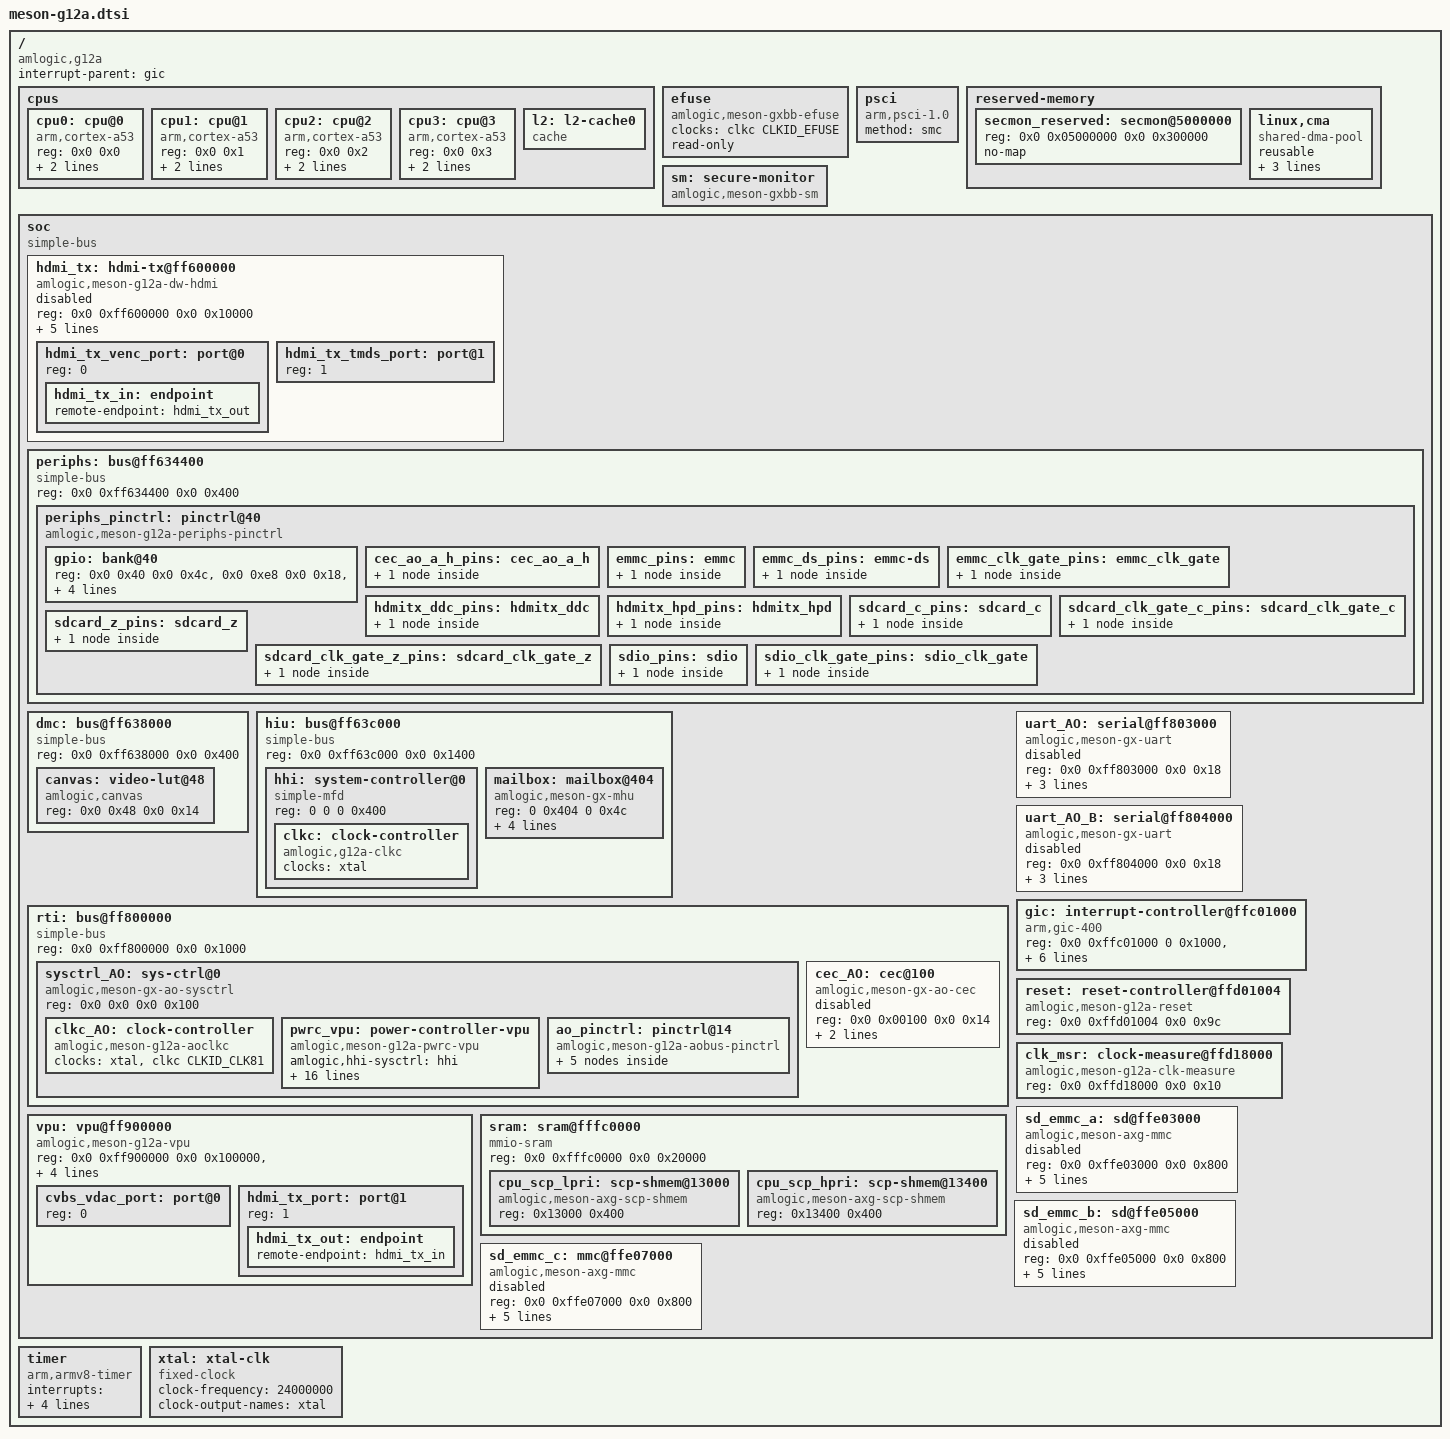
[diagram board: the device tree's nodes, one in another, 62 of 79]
// SPDX-License-Identifier: (GPL-2.0+ OR MIT)
/*
 * Copyright (c) 2018 Amlogic, Inc. All rights reserved.
 */

#include <dt-bindings/gpio/gpio.h>
#include <dt-bindings/clock/g12a-clkc.h>
#include <dt-bindings/gpio/gpio.h>
#include <dt-bindings/gpio/meson-g12a-gpio.h>
#include <dt-bindings/clock/g12a-aoclkc.h>
#include <dt-bindings/reset/g12a-aoclkc.h>
#include <dt-bindings/interrupt-controller/irq.h>
#include <dt-bindings/interrupt-controller/arm-gic.h>
#include <dt-bindings/reset/amlogic,meson-g12a-reset.h>

/ {
	compatible = "amlogic,g12a";

	interrupt-parent = <&gic>;
	#address-cells = <2>;
	#size-cells = <2>;

	cpus {
		#address-cells = <0x2>;
		#size-cells = <0x0>;

		cpu0: cpu@0 {
			device_type = "cpu";
			compatible = "arm,cortex-a53", "arm,armv8";
			reg = <0x0 0x0>;
			enable-method = "psci";
			next-level-cache = <&l2>;
		};

		cpu1: cpu@1 {
			device_type = "cpu";
			compatible = "arm,cortex-a53", "arm,armv8";
			reg = <0x0 0x1>;
			enable-method = "psci";
			next-level-cache = <&l2>;
		};

		cpu2: cpu@2 {
			device_type = "cpu";
			compatible = "arm,cortex-a53", "arm,armv8";
			reg = <0x0 0x2>;
			enable-method = "psci";
			next-level-cache = <&l2>;
		};

		cpu3: cpu@3 {
			device_type = "cpu";
			compatible = "arm,cortex-a53", "arm,armv8";
			reg = <0x0 0x3>;
			enable-method = "psci";
			next-level-cache = <&l2>;
		};

		l2: l2-cache0 {
			compatible = "cache";
		};
	};

	efuse: efuse {
		compatible = "amlogic,meson-gxbb-efuse";
		clocks = <&clkc CLKID_EFUSE>;
		#address-cells = <1>;
		#size-cells = <1>;
		read-only;
	};

	psci {
		compatible = "arm,psci-1.0";
		method = "smc";
	};

	reserved-memory {
		#address-cells = <2>;
		#size-cells = <2>;
		ranges;

		/* 3 MiB reserved for ARM Trusted Firmware (BL31) */
		secmon_reserved: secmon@5000000 {
			reg = <0x0 0x05000000 0x0 0x300000>;
			no-map;
		};

		linux,cma {
			compatible = "shared-dma-pool";
			reusable;
			size = <0x0 0x10000000>;
			alignment = <0x0 0x400000>;
			linux,cma-default;
		};
	};

	sm: secure-monitor {
		compatible = "amlogic,meson-gxbb-sm";
	};

	soc {
		compatible = "simple-bus";
		#address-cells = <2>;
		#size-cells = <2>;
		ranges;

		hdmi_tx: hdmi-tx@ff600000 {
			compatible = "amlogic,meson-g12a-dw-hdmi";
			reg = <0x0 0xff600000 0x0 0x10000>;
			interrupts = <GIC_SPI 57 IRQ_TYPE_EDGE_RISING>;
			resets = <&reset RESET_HDMITX_CAPB3>,
				 <&reset RESET_HDMITX_PHY>,
				 <&reset RESET_HDMITX>;
			reset-names = "hdmitx_apb", "hdmitx", "hdmitx_phy";
			clocks = <&clkc CLKID_HTX_PCLK>,
				 <&clkc CLKID_CLK81>,
				 <&clkc CLKID_VPU_INTR>;
			clock-names = "isfr", "iahb", "venci";
			#address-cells = <1>;
			#size-cells = <0>;
			status = "disabled";

			/* VPU VENC Input */
			hdmi_tx_venc_port: port@0 {
				reg = <0>;

				hdmi_tx_in: endpoint {
					remote-endpoint = <&hdmi_tx_out>;
				};
			};

			/* TMDS Output */
			hdmi_tx_tmds_port: port@1 {
				reg = <1>;
			};
		};

		periphs: bus@ff634400 {
			compatible = "simple-bus";
			reg = <0x0 0xff634400 0x0 0x400>;
			#address-cells = <2>;
			#size-cells = <2>;
			ranges = <0x0 0x0 0x0 0xff634400 0x0 0x400>;

			periphs_pinctrl: pinctrl@40 {
				compatible = "amlogic,meson-g12a-periphs-pinctrl";
				#address-cells = <2>;
				#size-cells = <2>;
				ranges;

				gpio: bank@40 {
					reg = <0x0 0x40  0x0 0x4c>,
					      <0x0 0xe8  0x0 0x18>,
					      <0x0 0x120 0x0 0x18>,
					      <0x0 0x2c0 0x0 0x40>,
					      <0x0 0x340 0x0 0x1c>;
					reg-names = "gpio",
						    "pull",
						    "pull-enable",
						    "mux",
						    "ds";
					gpio-controller;
					#gpio-cells = <2>;
					gpio-ranges = <&periphs_pinctrl 0 0 86>;
				};

				cec_ao_a_h_pins: cec_ao_a_h {
					mux {
						groups = "cec_ao_a_h";
						funcion = "cec_ao_a_h";
						bias-disable;
					};
				};

				emmc_pins: emmc {
					mux {
						groups = "emmc_nand_d0",
							 "emmc_nand_d1",
							 "emmc_nand_d2",
							 "emmc_nand_d3",
							 "emmc_nand_d4",
							 "emmc_nand_d5",
							 "emmc_nand_d6",
							 "emmc_nand_d7",
							 "emmc_clk",
							 "emmc_cmd";
						function = "emmc";
						bias-disable;
					};
				};

				emmc_ds_pins: emmc-ds {
					mux {
						groups = "emmc_nand_ds";
						function = "emmc";
						bias-disable;
					};
				};

				emmc_clk_gate_pins: emmc_clk_gate {
					mux {
						groups = "BOOT_8";
						function = "gpio_periphs";
						bias-pull-down;
					};
				};

				hdmitx_ddc_pins: hdmitx_ddc {
					mux {
						groups = "hdmitx_sda",
							 "hdmitx_sck";
						function = "hdmitx";
						bias-disable;
					};
				};

				hdmitx_hpd_pins: hdmitx_hpd {
					mux {
						groups = "hdmitx_hpd_in";
						function = "hdmitx";
						bias-disable;
					};
				};

				sdcard_c_pins: sdcard_c {
					mux {
						groups = "sdcard_d0_c",
							 "sdcard_d1_c",
							 "sdcard_d2_c",
							 "sdcard_d3_c",
							 "sdcard_cmd_c",
							 "sdcard_clk_c";
						function = "sdcard";
						bias-disable;
					};
				};

				sdcard_clk_gate_c_pins: sdcard_clk_gate_c {
					mux {
						groups = "GPIOC_4";
						function = "gpio_periphs";
						bias-pull-down;
					};
				};

				sdcard_z_pins: sdcard_z {
					mux {
						groups = "sdcard_d0_z",
							 "sdcard_d1_z",
							 "sdcard_d2_z",
							 "sdcard_d3_z",
							 "sdcard_cmd_z",
							 "sdcard_clk_z";
						function = "sdcard";
						bias-disable;
					};
				};

				sdcard_clk_gate_z_pins: sdcard_clk_gate_z {
					mux {
						groups = "GPIOZ_6";
						function = "gpio_periphs";
						bias-pull-down;
					};
				};

				sdio_pins: sdio {
					mux {
						groups = "sdio_d0",
							 "sdio_d1",
							 "sdio_d2",
							 "sdio_d3",
							 "sdio_cmd",
							 "sdio_clk";
						function = "sdio";
						bias-disable;
					};
				};

				sdio_clk_gate_pins: sdio_clk_gate {
					mux {
						groups = "GPIOX_4";
						function = "gpio_periphs";
						bias-pull-down;
					};
				};
			};
		};

		dmc: bus@ff638000 {
			compatible = "simple-bus";
			reg = <0x0 0xff638000 0x0 0x400>;
			#address-cells = <2>;
			#size-cells = <2>;
			ranges = <0x0 0x0 0x0 0xff638000 0x0 0x400>;

			canvas: video-lut@48 {
				compatible = "amlogic,canvas";
				reg = <0x0 0x48 0x0 0x14>;
			};
		};

		hiu: bus@ff63c000 {
			compatible = "simple-bus";
			reg = <0x0 0xff63c000 0x0 0x1400>;
			#address-cells = <2>;
			#size-cells = <2>;
			ranges = <0x0 0x0 0x0 0xff63c000 0x0 0x1400>;

			hhi: system-controller@0 {
				compatible = "simple-mfd", "syscon";
				reg = <0 0 0 0x400>;

				clkc: clock-controller {
					compatible = "amlogic,g12a-clkc";
					#clock-cells = <1>;
					clocks = <&xtal>;
					clock-names = "xtal";
				};
			};

			mailbox: mailbox@404 {
				compatible = "amlogic,meson-gx-mhu", "amlogic,meson-gxbb-mhu";
				reg = <0 0x404 0 0x4c>;
				interrupts = <GIC_SPI 208 IRQ_TYPE_EDGE_RISING>,
					     <GIC_SPI 209 IRQ_TYPE_EDGE_RISING>,
					     <GIC_SPI 210 IRQ_TYPE_EDGE_RISING>;
				clocks = <&clkc_AO CLKID_AO_MAILBOX>;
				clock-names = "pclk";
				#mbox-cells = <1>;
			};

		};

		rti: bus@ff800000 {
			compatible = "simple-bus";
			reg = <0x0 0xff800000 0x0 0x1000>;
			#address-cells = <2>;
			#size-cells = <2>;
			ranges = <0x0 0x0 0x0 0xff800000 0x0 0x1000>;

			sysctrl_AO: sys-ctrl@0 {
				compatible = "amlogic,meson-gx-ao-sysctrl", "simple-mfd", "syscon";
				reg =  <0x0 0x0 0x0 0x100>;
				#address-cells = <2>;
				#size-cells = <2>;
				ranges = <0x0 0x0 0x0 0x0 0x0 0x100>;


				clkc_AO: clock-controller {
					compatible = "amlogic,meson-g12a-aoclkc";
					#clock-cells = <1>;
					#reset-cells = <1>;
					clocks = <&xtal>, <&clkc CLKID_CLK81>;
					clock-names = "xtal", "mpeg-clk";
				};

				pwrc_vpu: power-controller-vpu {
					compatible = "amlogic,meson-g12a-pwrc-vpu";
					#power-domain-cells = <0>;
					amlogic,hhi-sysctrl = <&hhi>;
					resets = <&reset RESET_VIU>,
						 <&reset RESET_VENC>,
						 <&reset RESET_VCBUS>,
						 <&reset RESET_BT656>,
						 <&reset RESET_RDMA>,
						 <&reset RESET_VENCI>,
						 <&reset RESET_VENCP>,
						 <&reset RESET_VDAC>,
						 <&reset RESET_VDI6>,
						 <&reset RESET_VENCL>,
						 <&reset RESET_VID_LOCK>;
					clocks = <&clkc CLKID_VPU>,
						 <&clkc CLKID_VAPB>;
					clock-names = "vpu", "vapb";
					/*
					 * VPU clocking is provided by two identical clock paths
					 * VPU_0 and VPU_1 muxed to a single clock by a glitch
					 * free mux to safely change frequency while running.
					 * Same for VAPB but with a final gate after the glitch free mux.
					 */
					assigned-clocks = <&clkc CLKID_VPU_0_SEL>,
							  <&clkc CLKID_VPU_0>,
							  <&clkc CLKID_VPU>, /* Glitch free mux */
							  <&clkc CLKID_VAPB_0_SEL>,
							  <&clkc CLKID_VAPB_0>,
							  <&clkc CLKID_VAPB_SEL>; /* Glitch free mux */
					assigned-clock-parents = <&clkc CLKID_FCLK_DIV3>,
								 <0>, /* Do Nothing */
								 <&clkc CLKID_VPU_0>,
								 <&clkc CLKID_FCLK_DIV4>,
								 <0>, /* Do Nothing */
								 <&clkc CLKID_VAPB_0>;
					assigned-clock-rates = <0>, /* Do Nothing */
							       <666666666>,
							       <0>, /* Do Nothing */
							       <0>, /* Do Nothing */
							       <250000000>,
							       <0>; /* Do Nothing */
				};

				ao_pinctrl: pinctrl@14 {
					compatible = "amlogic,meson-g12a-aobus-pinctrl";
					#address-cells = <2>;
					#size-cells = <2>;
					ranges;

					gpio_ao: bank@14 {
						reg = <0x0 0x14 0x0 0x8>,
						      <0x0 0x1c 0x0 0x8>,
						      <0x0 0x24 0x0 0x14>;
						reg-names = "mux",
							    "ds",
							    "gpio";
						gpio-controller;
						#gpio-cells = <2>;
						gpio-ranges = <&ao_pinctrl 0 0 15>;
					};

					uart_ao_a_pins: uart_a_ao {
						mux {
							groups = "uart_ao_a_tx",
								 "uart_ao_a_rx";
							function = "uart_ao_a";
							bias-disable;
						};
					};

					uart_ao_a_cts_rts_pins: uart_ao_a_cts_rts {
						mux {
							groups = "uart_ao_a_cts",
								 "uart_ao_a_rts";
							function = "uart_ao_a";
							bias-disable;
						};
					};
				};
			};

			cec_AO: cec@100 {
				compatible = "amlogic,meson-gx-ao-cec",
					     "amlogic,meson-g12a-ao-cec";
				reg = <0x0 0x00100 0x0 0x14>;
				interrupts = <GIC_SPI 199 IRQ_TYPE_EDGE_RISING>;
				clocks = <&clkc_AO CLKID_AO_CEC>;
				clock-names = "core";
				status = "disabled";
			};
		};

		uart_AO: serial@ff803000 {
			compatible = "amlogic,meson-gx-uart",
				     "amlogic,meson-ao-uart";
			reg = <0x0 0xff803000 0x0 0x18>;
			interrupts = <GIC_SPI 193 IRQ_TYPE_EDGE_RISING>;
			clocks = <&xtal>, <&clkc_AO CLKID_AO_UART>, <&xtal>;
			clock-names = "xtal", "pclk", "baud";
			reset = <&clkc_AO RESET_AO_UART>;
			status = "disabled";
		};

		uart_AO_B: serial@ff804000 {
			compatible = "amlogic,meson-gx-uart",
				     "amlogic,meson-ao-uart";
			reg = <0x0 0xff804000 0x0 0x18>;
			interrupts = <GIC_SPI 197 IRQ_TYPE_EDGE_RISING>;
			clocks = <&xtal>, <&clkc_AO CLKID_AO_UART2>, <&xtal>;
			clock-names = "xtal", "pclk", "baud";
			reset = <&clkc_AO RESET_AO_UART2>;
			status = "disabled";
		};

		vpu: vpu@ff900000 {
			compatible = "amlogic,meson-g12a-vpu";
			reg = <0x0 0xff900000 0x0 0x100000>,
			      <0x0 0xff63c000 0x0 0x1000>;
			reg-names = "vpu", "hhi";
			interrupts = <GIC_SPI 3 IRQ_TYPE_EDGE_RISING>;
			#address-cells = <1>;
			#size-cells = <0>;
			amlogic,canvas = <&canvas>;
			power-domains = <&pwrc_vpu>;

			/* CVBS VDAC output port */
			cvbs_vdac_port: port@0 {
				reg = <0>;
			};

			/* HDMI-TX output port */
			hdmi_tx_port: port@1 {
				reg = <1>;

				hdmi_tx_out: endpoint {
					remote-endpoint = <&hdmi_tx_in>;
				};
			};
		};

		sram: sram@fffc0000 {
			compatible = "mmio-sram";
			reg = <0x0 0xfffc0000 0x0 0x20000>;
			#address-cells = <1>;
			#size-cells = <1>;
			ranges = <0 0x0 0xfffc0000 0x20000>;

			cpu_scp_lpri: scp-shmem@13000 {
				compatible = "amlogic,meson-axg-scp-shmem";
				reg = <0x13000 0x400>;
			};

			cpu_scp_hpri: scp-shmem@13400 {
				compatible = "amlogic,meson-axg-scp-shmem";
				reg = <0x13400 0x400>;
			};
		};

		gic: interrupt-controller@ffc01000 {
			compatible = "arm,gic-400";
			reg = <0x0 0xffc01000 0 0x1000>,
			      <0x0 0xffc02000 0 0x2000>,
			      <0x0 0xffc04000 0 0x2000>,
			      <0x0 0xffc06000 0 0x2000>;
			interrupt-controller;
			interrupts = <GIC_PPI 9
				(GIC_CPU_MASK_SIMPLE(8) | IRQ_TYPE_LEVEL_HIGH)>;
			#interrupt-cells = <3>;
			#address-cells = <0>;
		};

		reset: reset-controller@ffd01004 {
			compatible = "amlogic,meson-g12a-reset",
				     "amlogic,meson-axg-reset";
			reg = <0x0 0xffd01004 0x0 0x9c>;
			#reset-cells = <1>;
		};

		clk_msr: clock-measure@ffd18000 {
			compatible = "amlogic,meson-g12a-clk-measure";
			reg = <0x0 0xffd18000 0x0 0x10>;
		};

		sd_emmc_a: sd@ffe03000 {
			compatible = "amlogic,meson-axg-mmc";
			reg = <0x0 0xffe03000 0x0 0x800>;
			interrupts = <GIC_SPI 189 IRQ_TYPE_EDGE_RISING>;
			status = "disabled";
			clocks = <&clkc CLKID_SD_EMMC_A>,
				 <&clkc CLKID_SD_EMMC_A_CLK0>,
				 <&clkc CLKID_FCLK_DIV2>;
			clock-names = "core", "clkin0", "clkin1";
			resets = <&reset RESET_SD_EMMC_A>;
		};

		sd_emmc_b: sd@ffe05000 {
			compatible = "amlogic,meson-axg-mmc";
			reg = <0x0 0xffe05000 0x0 0x800>;
			interrupts = <GIC_SPI 190 IRQ_TYPE_EDGE_RISING>;
			status = "disabled";
			clocks = <&clkc CLKID_SD_EMMC_B>,
				 <&clkc CLKID_SD_EMMC_B_CLK0>,
				 <&clkc CLKID_FCLK_DIV2>;
			clock-names = "core", "clkin0", "clkin1";
			resets = <&reset RESET_SD_EMMC_B>;
		};

		sd_emmc_c: mmc@ffe07000 {
			compatible = "amlogic,meson-axg-mmc";
			reg = <0x0 0xffe07000 0x0 0x800>;
			interrupts = <GIC_SPI 191 IRQ_TYPE_EDGE_RISING>;
			status = "disabled";
			clocks = <&clkc CLKID_SD_EMMC_C>,
				 <&clkc CLKID_SD_EMMC_C_CLK0>,
				 <&clkc CLKID_FCLK_DIV2>;
			clock-names = "core", "clkin0", "clkin1";
			resets = <&reset RESET_SD_EMMC_C>;
		};
	};

	timer {
		compatible = "arm,armv8-timer";
		interrupts = <GIC_PPI 13
			(GIC_CPU_MASK_RAW(0xff) | IRQ_TYPE_LEVEL_LOW)>,
			     <GIC_PPI 14
			(GIC_CPU_MASK_RAW(0xff) | IRQ_TYPE_LEVEL_LOW)>,
			     <GIC_PPI 11
			(GIC_CPU_MASK_RAW(0xff) | IRQ_TYPE_LEVEL_LOW)>,
			     <GIC_PPI 10
			(GIC_CPU_MASK_RAW(0xff) | IRQ_TYPE_LEVEL_LOW)>;
	};

	xtal: xtal-clk {
		compatible = "fixed-clock";
		clock-frequency = <24000000>;
		clock-output-names = "xtal";
		#clock-cells = <0>;
	};

};
